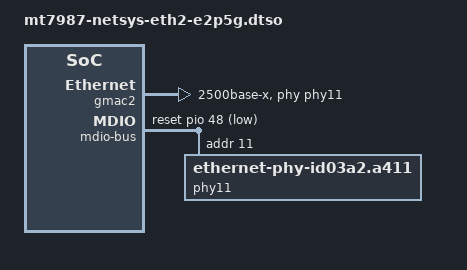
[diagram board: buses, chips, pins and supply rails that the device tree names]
// SPDX-License-Identifier: (GPL-2.0 OR MIT)

/dts-v1/;
/plugin/;

/ {
	fragment@0 {
		target-path = "/soc_netsys/ethernet@15100000";
		__overlay__ {
			gmac2: mac@2 {
				compatible = "mediatek,eth-mac";
				reg = <2>;
				phy-mode = "2500base-x";
				phy-handle = <&phy11>;
				pcs-handle = <&sgmiipcs1>;
			};
		};
	};

	fragment@1 {
		target-path = "/soc_netsys/hnat@15000000";
		__overlay__ {
			mtketh-lan2 = "eth2";
			mtketh-max-gmac = <3>;
		};
	};

	fragment@2 {
		target-path = "/soc_netsys/ethernet@15100000/mdio-bus";
		__overlay__ {
			reset-gpios = <&pio 48 1>;
			reset-delay-us = <10000>;

			phy11: phy@11 {
				compatible = "ethernet-phy-id03a2.a411";
				reg = <11>;
				phy-mode = "2500base-x";
				airoha,polarity = <1>;
				airoha,surge = <0>;
				airoha,phy-handle;
			};
		};
	};
};

